# M2003 register map
File version: 1.0
Registers are 32-bit, read-write, reset 0x0 unless marked. A register's access mark holds for its fields unless they carry their own. Offsets are from the block's base; [hi:lo] are bit positions; {n}, {i} and the like mark numbered series.

## FMC — FMC Register Map
Base 0x4000C000
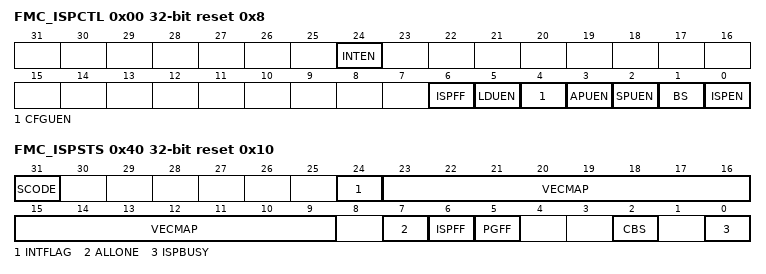
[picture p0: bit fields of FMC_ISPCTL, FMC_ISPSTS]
0x00 FMC_ISPCTL reset 0x8 — ISP Control Register
  [24] INTEN — INT Enable Bit (Write Protect). Note: This bit is write protected. Refer to the SYS_REGLCTL register. Before using INT, user needs to clear the INTFLAG(FMC_ISPSTS[24]) make sure INT happen at correct time.
    0=ISP INT Disabled; 1=ISP INT Enabled
  [6] ISPFF — ISP Fail Flag (Write Protect). This bit is set by hardware when a triggered ISP meets any of the following conditions: This bit needs to be cleared by writing 1 to it. APROM writes to itself if APUEN is set to 0. LDROM writes to itself if LDUEN is set to 0. CONFIG is erased/programmed if CFGUEN is set to 0. Page Erase command at LOCK mode with ICE connection. Erase or Program command at brown-out detected. Destination address is illegal, such as over an available range. Invalid ISP commands. Mass erase when MERASE (CFG0[13]) is disabled. Note: This bit is write protected. Refer to the SYS_REGLCTL register.
  [5] LDUEN — LDROM Update Enable Bit (Write Protect). Note: This bit is write protected. Refer to the SYS_REGLCTL register.
    0=LDROM cannot be updated; 1=LDROM can be updated
  [4] CFGUEN — CONFIG Update Enable Bit (Write Protect). Note: This bit is write protected. Refer to the SYS_REGLCTL register.
    0=CONFIG cannot be updated; 1=CONFIG can be updated
  [3] APUEN — APROM Update Enable Bit (Write Protect). Note: This bit is write protected. Refer to the SYS_REGLCTL register.
    0=APROM cannot be updated when the chip runs in APROM; 1=APROM can be updated when the chip runs in APROM
  [2] SPUEN — SPROM Update Enable Bit (Write Protect). Note: This bit is write protected. Refer to the SYS_REGLCTL register.
    0=SPROM cannot be updated; 1=SPROM can be updated
  [1] BS — Boot Select (Write Protect). Set/clear this bit to select next booting from LDROM/APROM, respectively. This bit also functions as chip booting status flag, which can be used to check where chip booted from. This bit is initiated with the inversed value of CBS (CONFIG0[7]) after any reset is happened except CPU reset (CPU is 1) or system reset (SYS) is happened. Note: This bit is write protected. Refer to the SYS_REGLCTL register.
    0=Booting from APROM; 1=Booting from LDROM
  [0] ISPEN ro — ISP Enable Flag Bit (Read Only). Note: This bit is read only to show ISP function enable.
    0=ISP function is Disabled status; 1=ISP function is Enabled status
0x04 FMC_ISPADDR — ISP Address Register
  [31:0] ISPADDR — ISP Address. The M2003C series is equipped with embedded Flash. ISPADDR[1:0] must be kept 00 for ISP 32-bit operation. I. For CRC32 Checksum Calculation command, this field is the Flash starting address for checksum calculation, 0.5 Kbytes alignment is necessary for CRC32 checksum calculation. For Flash32-bit Program, ISP address needs word alignment (4-byte).
0x08 FMC_ISPDAT — ISP Data Register
  [31:0] ISPDAT — ISP Data. Write data to this register before ISP program operation. Read data from this register after ISP read operation.
0x0C FMC_ISPCMD — ISP Command Register
  [6:0] CMD — ISP Command. The ISP command table is shown below: The other commands are invalid.
    0=FLASH Read; 4=Read Unique ID; 8=Read Flash All-One Result; 11=Read Company ID; 12=Read Device ID; 13=Read Checksum; 33=FLASH 32-bit Program; 34=FLASH Page Erase. Erase any page in APROM, LDROM and SPROM; 40=Run Flash All-One Verification; 45=Run Checksum Calculation; 46=Vector Remap
0x10 FMC_ISPTRG — ISP Trigger Control Register
  [0] ISPGO — ISP Start Trigger (Write Protect). Note: This bit is write protected. Refer to the SYS_REGLCTL register.
    0=ISP operation is finished; 1=ISP is progressed
0x40 FMC_ISPSTS reset 0x10 (reset mask 0xFFFFFF0) — ISP Status Register
  [31] SCODE — Security Code Active Flag. This bit is set by hardware when detecting SPROM secured code is active at Flash initiation, or software writes 1 to this bit to make secured code active; this bit is clear by SPROM page erase operation.
    0=Secured code is inactive; 1=Secured code is active
  [24] INTFLAG — ISP Interrupt Flag. Note: This function needs to be enabled by FMC_ISPCTRL[24].
    0=ISP Not Finished; 1=ISP done or ISPFF set
  [23:9] VECMAP ro — Vector Page Mapping Address (Read Only). All access to 0x0000_0000~0x0000_01FF is remapped to the Flash memory address {VECMAP[14:0], 9'h000} ~ {VECMAP[14:0], 9'h1FF}
  [7] ALLONE — Flash All-one Verification Flag. This bit is set by hardware if all of Flash bits are 1, and cleared if Flash bits are not all 1 after 'Run Flash All-One Verification' is complete; this bit also can be cleared by writing 1
    0=Flash bits are not all 1 after 'Run Flash All-One Verification' is complete; 1=All of Flash bits are 1 after 'Run Flash All-One Verification' is complete
  [6] ISPFF — ISP Fail Flag (Write Protect). This bit is the mirror of ISPFF (FMC_ISPCTL[6]), it needs to be cleared by writing 1 to FMC_ISPCTL[6] or FMC_ISPSTS[6]. This bit is set by hardware when a triggered ISP meets any of the following conditions: APROM writes to itself if APUEN is set to 0. LDROM writes to itself if LDUEN is set to 0. CONFIG is erased/programmed if CFGUEN is set to 0. Page Erase command at LOCK mode with ICE connection. Erase or Program command at brown-out detected. Destination address is illegal, such as over an available range. Invalid ISP commands. Mass erase when MERASE (CFG0[13]) is disabled. Note: This bit is write protected. Refer to the SYS_REGLCTL register.
  [5] PGFF ro — Flash Program with Fast Verification Flag (Read Only). This bit is set if data is mismatched at ISP programming verification. This bit is cleared by performing ISP Flash erase or ISP read CID operation
    0=Flash Program is success; 1=Flash Program is failed. Program data is different with data in the Flash memory
  [2] CBS ro — Boot Selection of CONFIG (Read Only). This bit is initiated with the CBS (CONFIG0[7]) after any reset is happened except CPU reset (CPU is 1) or system reset (SYS) is happened.
    0=LDROM with IAP mode; 1=APROM with IAP mode
  [0] ISPBUSY ro — ISP Busy Flag (Read Only). Write 1 to start ISP operation and this bit will be cleared to 0 by hardware automatically when ISP operation is finished. This bit is the mirror of ISPGO(FMC_ISPTRG[0]).
    0=ISP operation is finished; 1=ISP is progressed
0x4C FMC_CYCCTL reset 0x101 — Flash Access Cycle Control Register
  [3:0] CYCLE — Flash Access Cycle Control (Write Protect). This register is updated by software. User needs to check the speed of HCLK and set the cycle 0. The HCLK working frequency range is25 MHz. The others are reserved. Note: This bit is write protected. Refer to the SYS_REGLCTL register.
    1=Flash access cycle is 1
